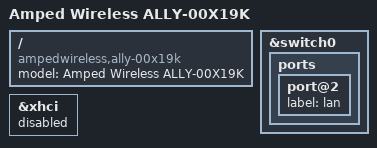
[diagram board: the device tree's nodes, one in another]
// SPDX-License-Identifier: GPL-2.0-or-later OR MIT

#include "mt7621_ampedwireless_ally.dtsi"

/ {
	compatible = "ampedwireless,ally-00x19k", "mediatek,mt7621-soc";
	model = "Amped Wireless ALLY-00X19K";
};

&switch0 {
	ports {
		port@2 {
			status = "okay";
			label = "lan";
		};
	};
};

&xhci {
	status = "disabled";
};
